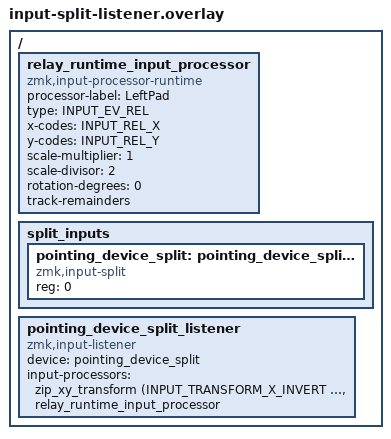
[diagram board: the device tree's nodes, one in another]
#include <zephyr/dt-bindings/input/input-event-codes.h>
#include <dt-bindings/zmk/input_transform.h>

/*
 * Independent runtime input processor for whatever is relayed over
 * zmk,input-split (double_ball's 2nd trackball, or the mini trackpad) -
 * deliberately its own node rather than the local trackball's
 * &mouse_runtime_input_processor singleton (torabo_tsuki_lp_right.overlay),
 * so the two show up as separate, independently tunable entries in DYA
 * Studio's Trackball tab (speed, rotation, invert, temp-layer, ...).
 *
 * Only headers are included here, never input/processors.dtsi or
 * runtime-input-processor.dtsi: the shield overlay already includes those
 * (so &zip_xy_transform and the "zmk,input-processor-runtime" binding are
 * available), and a snippet overlay is applied *after* the shield overlay.
 * Re-including a .dtsi here re-emits its nodes with their default
 * properties, silently undoing the shield's overrides - that is exactly
 * how &scroll_runtime_input_processor's x-codes/y-codes (REL_X/REL_Y) got
 * reset to HWHEEL/WHEEL, so it never matched trackball events and
 * scrolling stopped working in every build using this snippet.
 *
 * Default speed halved (1/2) versus the trackball's 1/1: the mini trackpad
 * felt too fast at full speed. Adjust further live from DYA Studio from
 * here on - no rebuild needed.
 *
 * processor-label is capped at 8 chars (BLE). "LeftPad" fits; if this ever
 * relays double_ball's 2nd trackball instead of the mini trackpad, rename
 * it to something ball-appropriate.
 */
/{
    relay_runtime_input_processor: relay_runtime_input_processor {
        compatible = "zmk,input-processor-runtime";
        processor-label = "LeftPad";
        type = <INPUT_EV_REL>;
        x-codes = <INPUT_REL_X>;
        y-codes = <INPUT_REL_Y>;
        scale-multiplier = <1>;
        scale-divisor = <2>;
        rotation-degrees = <0>;
        track-remainders;
        #input-processor-cells = <0>;
    };

    split_inputs {
        #address-cells = <1>;
        #size-cells = <0>;

        pointing_device_split: pointing_device_split@0 {
            compatible = "zmk,input-split";
            reg = <0>;
        };
    };

    pointing_device_split_listener: pointing_device_split_listener {
        compatible = "zmk,input-listener";
        device = <&pointing_device_split>;
        status = "okay";
        input-processors = <&zip_xy_transform (INPUT_TRANSFORM_X_INVERT | INPUT_TRANSFORM_Y_INVERT)>, <&relay_runtime_input_processor>;
     };
};
